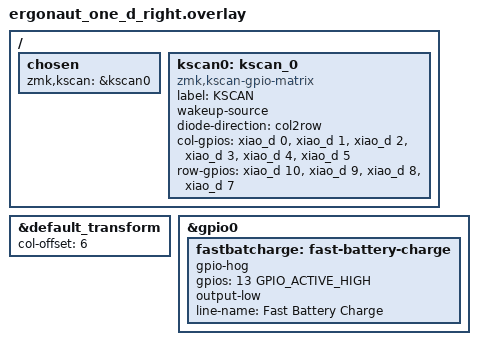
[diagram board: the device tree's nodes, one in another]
#include <dt-bindings/zmk/matrix_transform.h>

#include "ergonaut_one_d.dtsi"

/ {
    chosen {
        zmk,kscan = &kscan0;
    };

	kscan0: kscan_0 {
		compatible = "zmk,kscan-gpio-matrix";
		label = "KSCAN";
		wakeup-source;

		diode-direction = "col2row";
        col-gpios
            = <&xiao_d 0 GPIO_ACTIVE_HIGH>
            , <&xiao_d 1 GPIO_ACTIVE_HIGH>
            , <&xiao_d 2 GPIO_ACTIVE_HIGH>
            , <&xiao_d 3 GPIO_ACTIVE_HIGH>
            , <&xiao_d 4 GPIO_ACTIVE_HIGH>
            , <&xiao_d 5 GPIO_ACTIVE_HIGH>
            ;
		row-gpios
			= <&xiao_d 10 (GPIO_ACTIVE_HIGH | GPIO_PULL_DOWN)>
			, <&xiao_d  9 (GPIO_ACTIVE_HIGH | GPIO_PULL_DOWN)>
			, <&xiao_d  8 (GPIO_ACTIVE_HIGH | GPIO_PULL_DOWN)>
			, <&xiao_d  7 (GPIO_ACTIVE_HIGH | GPIO_PULL_DOWN)>
			;
	};
};

&default_transform {
    col-offset = <6>;
};

&gpio0 {
    fastbatcharge: fast-battery-charge {
        gpio-hog;
        gpios = <13 GPIO_ACTIVE_HIGH>;
        output-low;
        line-name = "Fast Battery Charge";
    };
};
